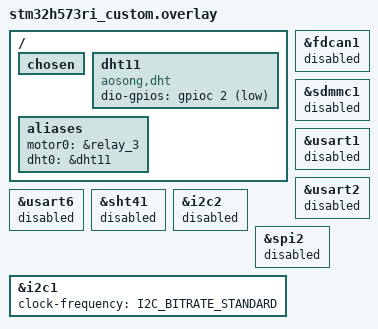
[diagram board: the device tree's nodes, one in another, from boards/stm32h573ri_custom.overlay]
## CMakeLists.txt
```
cmake_minimum_required(VERSION 3.20.0)
find_package(Zephyr REQUIRED HINTS $ENV{ZEPHYR_BASE})
project(fw_showcase VERSION 3.1.0)

# Headers the Zephyr libraries must see (Mbed TLS user config)
zephyr_include_directories(src/modules/MQTT/TLS)

# One folder per module under src/modules
set(MODULES_DIR ${CMAKE_CURRENT_SOURCE_DIR}/src/modules)

target_include_directories(app PRIVATE
  ${MODULES_DIR}/Alarm
  ${MODULES_DIR}/Boot
  ${MODULES_DIR}/Config
  ${MODULES_DIR}/DHT11
  ${MODULES_DIR}/LCD
  ${MODULES_DIR}/Motor
  ${MODULES_DIR}/MQTT
  ${MODULES_DIR}/Network
  ${MODULES_DIR}/RS485
  ${MODULES_DIR}/StatusLED
  ${MODULES_DIR}/WebServer
)

target_sources(app PRIVATE
  src/main.c

  ${MODULES_DIR}/Alarm/alarm.c
  ${MODULES_DIR}/Alarm/alarm_notify.c
  ${MODULES_DIR}/Boot/boot_swap.c
  ${MODULES_DIR}/Config/app_config.c
  ${MODULES_DIR}/Config/app_state.c
  ${MODULES_DIR}/DHT11/dht11.c
  ${MODULES_DIR}/LCD/lcd_pcf8574.c
  ${MODULES_DIR}/LCD/lcd_view.c
  ${MODULES_DIR}/Motor/motor.c
  ${MODULES_DIR}/MQTT/mqtt_app.c
  ${MODULES_DIR}/Network/network.c
  ${MODULES_DIR}/RS485/rs485.c
  ${MODULES_DIR}/RS485/rs485_cmd.c
  ${MODULES_DIR}/StatusLED/status_led.c
  ${MODULES_DIR}/WebServer/http.c
  ${MODULES_DIR}/WebServer/web_server.c
)
```

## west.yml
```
# west manifest for fw_showcase.
#
#   west init -l --mf fw_showcase/west.yml fptUniversity
#   (run from the directory that holds the fptUniversity clone)
#   west update
#
# Only the modules this firmware needs are fetched.
manifest:
  version: "1.2"

  remotes:
    - name: zephyrproject-rtos
      url-base: https://github.com/zephyrproject-rtos

  projects:
    - name: zephyr
      remote: zephyrproject-rtos
      revision: v4.4.2
      import:
        name-allowlist:
          - cmsis
          - cmsis_6
          - hal_stm32
          - mbedtls
          - mcuboot
          - picolibc
          - segger
          - tf-psa-crypto
          - zcbor

  self:
    path: fptUniversity
```

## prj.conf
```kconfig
# fw_showcase 3.1.0 — DHT11 + LCD + web/MQTT + alarm (RS485, relay, motor)
CONFIG_BOOT_BANNER=y
CONFIG_PRINTK=y
CONFIG_LOG=y
CONFIG_LOG_DEFAULT_LEVEL=3
CONFIG_STDOUT_CONSOLE=y

# Console over SEGGER RTT (read through the SWD probe, no UART adapter):
# printk and the log both go to RTT channel 0. UART5 stays free.
CONFIG_USE_SEGGER_RTT=y
CONFIG_RTT_CONSOLE=y
CONFIG_UART_CONSOLE=n
CONFIG_LOG_BACKEND_UART=n
CONFIG_LOG_BACKEND_RTT=y
# Keep SWD reachable while the idle thread sits in WFI
CONFIG_STM32_ENABLE_DEBUG_SLEEP_STOP=y
CONFIG_GPIO=y
CONFIG_BOOTLOADER_MCUBOOT=y
CONFIG_FLASH=y
CONFIG_FLASH_MAP=y
CONFIG_FLASH_PAGE_LAYOUT=y
CONFIG_IMG_MANAGER=y
CONFIG_MCUBOOT_IMG_MANAGER=y
CONFIG_STREAM_FLASH=y
CONFIG_IMG_ERASE_PROGRESSIVELY=y
CONFIG_REBOOT=y

# DHT11 (PC2). The bit timing is decoded by busy polling, keep IRQs from
# stretching the measured pulses.
CONFIG_SENSOR=y
CONFIG_DHT=y
CONFIG_DHT_LOCK_IRQS=y

# 20x4 LCD (PCF8574 on I2C1)
CONFIG_I2C=y

# RS485 (UART4): polled TX, interrupt-driven RX for ON/OFF commands
CONFIG_SERIAL=y
CONFIG_UART_INTERRUPT_DRIVEN=y

# W5500 Ethernet
CONFIG_SPI=y
CONFIG_ETH_W5500=y
CONFIG_NET_L2_ETHERNET=y
CONFIG_NETWORKING=y
CONFIG_NET_IPV4=y
CONFIG_NET_TCP=y
CONFIG_NET_SOCKETS=y
CONFIG_NET_DHCPV4=y
# IP is assigned at runtime in main.c (DHCP or static per web config).
# net_config auto-init + compile-time static are disabled so they don't
# force 192.168.1.100 before the DHCP client can request a lease.
CONFIG_NET_MGMT=y
CONFIG_NET_MGMT_EVENT=y
CONFIG_POSIX_API=y

# Thread / memory
CONFIG_MAIN_STACK_SIZE=4096
CONFIG_NET_TX_STACK_SIZE=2048
CONFIG_NET_RX_STACK_SIZE=2048
CONFIG_SYSTEM_WORKQUEUE_STACK_SIZE=2048
CONFIG_ZVFS_POLL_MAX=6
CONFIG_NET_MAX_CONN=8
CONFIG_NET_MAX_CONTEXTS=12

CONFIG_HEAP_MEM_POOL_SIZE=16384

# ── MQTT client + DNS ──
CONFIG_MQTT_LIB=y
CONFIG_DNS_RESOLVER=y
CONFIG_DNS_SERVER_IP_ADDRESSES=y
CONFIG_DNS_SERVER1="8.8.8.8"

# ── TLS for MQTT (port 8883, broker certificate verified against ISRG Root X1) ──
CONFIG_MQTT_LIB_TLS=y
CONFIG_NET_SOCKETS_SOCKOPT_TLS=y
CONFIG_NET_SOCKETS_TLS_MAX_CONTEXTS=2
CONFIG_NET_SOCKETS_TLS_CONNECT_TIMEOUT=10000
CONFIG_TLS_CREDENTIALS=y
CONFIG_MBEDTLS=y
CONFIG_MBEDTLS_ENABLE_HEAP=y
CONFIG_MBEDTLS_HEAP_SIZE=65536
# 16 KB input records; the output buffer is reduced to 2 KB in
# src/modules/MQTT/TLS/mbedtls_user_config.h
CONFIG_MBEDTLS_SSL_MAX_CONTENT_LEN=16384
CONFIG_MBEDTLS_USER_CONFIG_FILE="mbedtls_user_config.h"
CONFIG_MBEDTLS_SSL_SERVER_NAME_INDICATION=y
CONFIG_MBEDTLS_SSL_PROTO_TLS1_3=y
CONFIG_MBEDTLS_SSL_TLS1_3_KEY_EXCHANGE_MODE_EPHEMERAL_ENABLED=y
CONFIG_MBEDTLS_CIPHERSUITE_TLS1_3_AES_128_GCM_SHA256=y
CONFIG_MBEDTLS_CIPHERSUITE_TLS_ECDHE_ECDSA_WITH_AES_128_GCM_SHA256=y
CONFIG_MBEDTLS_CIPHERSUITE_TLS_ECDHE_RSA_WITH_AES_128_GCM_SHA256=y
CONFIG_MBEDTLS_X509_CRT_PARSE_C=y
CONFIG_MBEDTLS_PEM_PARSE_C=y
CONFIG_PSA_WANT_ALG_SHA_384=y
```

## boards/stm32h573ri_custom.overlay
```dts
/*
 * fw_showcase: DHT11 + alarm motor on the Base Board U16 expansion header.
 *
 *   U16-5  PC2  DHT11 DATA   (SPI2 MISO on the board, SPI2 disabled below)
 *   CN3-5/6     Relay 3 (PA15) switches the motor, high = on
 *   U16-10 PB6  I2C1 SCL -> PCF8574 backpack of the 20x4 LCD
 *   U16-9  PB9  I2C1 SDA -> PCF8574 backpack of the 20x4 LCD
 *   U16-12 PA10 button      (unchanged, toggles the motor)
 *
 * The board devicetree is left untouched; everything showcase specific is here.
 */

/ {
	chosen {
		/delete-property/ zephyr,canbus;
	};

	dht11: dht11 {
		compatible = "aosong,dht";
		/* Open drain: the line is only ever pulled low by the MCU; the
		 * internal pull-up is weak, add an external 4.7k-10k if the module
		 * has none. */
		dio-gpios = <&gpioc 2 (GPIO_ACTIVE_LOW | GPIO_OPEN_DRAIN | GPIO_PULL_UP)>;
	};

	aliases {
		/* Motor switched by Relay 3 (PA15, high = contact closed):
		 * supply (+) -> CN3-5 COM3, CN3-6 OUT3 -> motor -> supply (-) */
		motor0 = &relay_3;
		dht0 = &dht11;
	};
};

/* Peripherals not used by the showcase */
&fdcan1 { status = "disabled"; };
&sdmmc1 { status = "disabled"; };
&usart1 { status = "disabled"; };
&usart2 { status = "disabled"; };  /* PA2/PA3 free on U16 */
&usart6 { status = "disabled"; };
&sht41  { status = "disabled"; };  /* replaced by the DHT11 */
&i2c2   { status = "disabled"; };
&spi2   { status = "disabled"; };  /* ST7920 replaced by the I2C LCD */

/* 20x4 LCD backpack: the PCF8574 is specified for 100 kHz only */
&i2c1 {
	clock-frequency = <I2C_BITRATE_STANDARD>;
};
```

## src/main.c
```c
/* fw_showcase: DHT11 (PC2) -> 20x4 LCD (PCF8574, I2C1), live web page, MQTT
 * status every 30 s, abnormal value -> RS485 alarm + relay 1 blink + motor.
 * Motor (Relay 3, PA15): web switch, RS485 ON/OFF, PA10 button or the alarm.
 * Config stored in flash — load at boot, edit via browser */
#include <zephyr/kernel.h>
#include <zephyr/sys/printk.h>
#include <errno.h>

#include "alarm.h"
#include "alarm_notify.h"
#include "app_config.h"
#include "app_state.h"
#include "boot_swap.h"
#include "dht11.h"
#include "lcd_view.h"
#include "motor.h"
#include "mqtt_app.h"
#include "network.h"
#include "rs485.h"
#include "status_led.h"
#include "version.h"

#define DHT_READ_PERIOD_MS      2000    /* DHT11 needs >= 1 s between reads */
#define REPORT_PERIOD_MS       30000    /* MQTT status period (web: every read) */
#define ALARM_REPEAT_PERIOD_MS 10000    /* RS485 ALARM repeat while active */
#define SPLASH_MS               5000    /* boot screen, then the status screen */

/* Load config from flash; fall back to defaults */
static void load_config(void)
{
    if (config_load(&g_cfg) != 0) {
        printk("[CFG] No saved config — loading defaults\n");
        config_defaults(&g_cfg);
    } else {
        printk("[CFG] Config loaded from flash\n");
    }
    printk("[CFG] IP mode=%s\n", g_cfg.ip_mode ? "Static" : "DHCP");
}

int main(void)
{
    printk("\n== fw_showcase v%s ==\n", FW_VERSION);

    load_config();

    boot_swap_confirm_image();
    if (!status_led_init()) return -1;
    boot_swap_check();

    rs485_init();
    bool dht_ok = dht11_init();
    motor_init();
    alarm_init();
    lcd_view_init();

    /* Ethernet comes up in the background (DHCP or static per config) */
    network_start();

    /* Boot screen for SPLASH_MS; it also covers the DHT11's ~1 s power-up
     * delay */
    status_led_heartbeat_start();
    int64_t splash_end = k_uptime_get() + SPLASH_MS;
    while (k_uptime_get() < splash_end) {
        status_led_heartbeat();
        k_msleep(20);
    }

    lcd_view_clear();
    lcd_view_show(false, 0, 0);

    int t = 0, h = 0;
    bool have_data = false;
    int64_t next_read   = k_uptime_get();
    int64_t next_report = next_read;              /* first report right away */
    int64_t next_repeat = 0;

    while (1) {
        int64_t now = k_uptime_get();

        if (now >= next_read) {
            next_read = now + DHT_READ_PERIOD_MS;

            int nt, nh;
            int rc = dht_ok ? dht11_read(&nt, &nh) : -ENODEV;
            bool ok = (rc == 0);
            if (ok) { t = nt; h = nh; have_data = true; }

            network_update_ip();
            enum alarm_event ev = alarm_update(ok, t, h);

            if (ok) printk("| T=%dC | H=%d%% | IP=%s | %s | MOTOR:%s   |\n", t, h, g_device_ip,
                           alarm_active() ? alarm_reason_str(alarm_reason()) : "OK",
                           motor_is_on() ? "ON" : "OFF");
            else    printk("| DHT11 read error %d | %s |\n", rc,
                           alarm_active() ? alarm_reason_str(alarm_reason()) : "OK");

            /* RS485: at once on start/clear, then every 10 s while active */
            if (ev == ALARM_EVT_START) {
                alarm_notify_rs485(ok, t, h, false);
                next_repeat = now + ALARM_REPEAT_PERIOD_MS;
            } else if (ev == ALARM_EVT_CLEAR) {
                alarm_notify_rs485(ok, t, h, true);
            } else if (alarm_active() && now >= next_repeat) {
                alarm_notify_rs485(ok, t, h, false);
                next_repeat = now + ALARM_REPEAT_PERIOD_MS;
            }

            /* Web: every read. MQTT: every 30 s and at once on an alarm
             * change (motor changes are pushed by motor.c). */
            app_state_update(t, h, ok, have_data);
            if (ev != ALARM_EVT_NONE || now >= next_report) {
                next_report = now + REPORT_PERIOD_MS;
                mqtt_app_publish_now();
            }

            lcd_view_retry(now);
            lcd_view_show(have_data, dht11_last_temp_x10(), dht11_last_humi_x10());
        } else {
            lcd_view_refresh();
        }

        status_led_heartbeat();
        k_msleep(20);
    }
    return 0;
}
```
